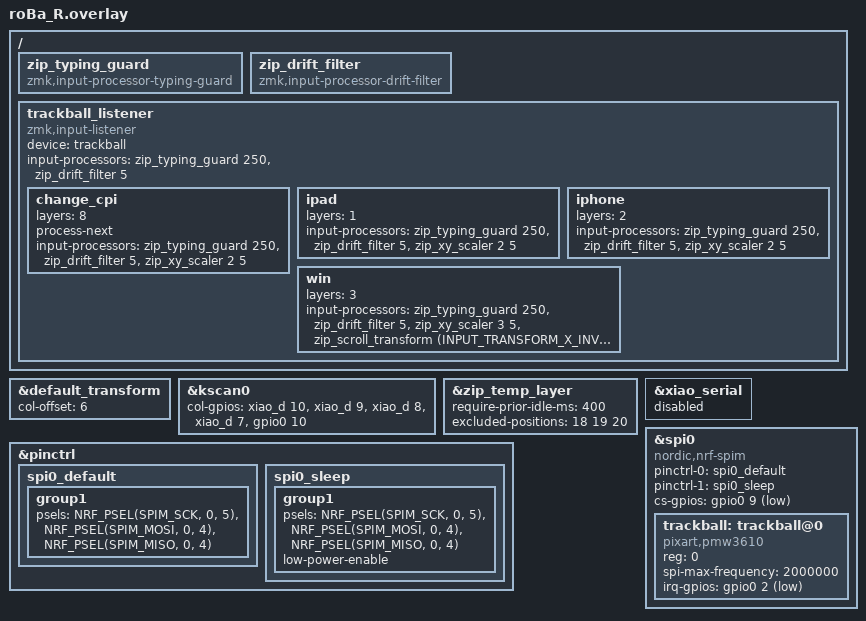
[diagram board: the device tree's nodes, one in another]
#include "roBa.dtsi"
#include <input/processors.dtsi>
#include <dt-bindings/zmk/input_transform.h>

&default_transform {
    col-offset = <6>;
};

&kscan0 {
        col-gpios
            = <&xiao_d 10 GPIO_ACTIVE_HIGH>
            , <&xiao_d 9 GPIO_ACTIVE_HIGH>
            , <&xiao_d 8 GPIO_ACTIVE_HIGH>
            , <&xiao_d 7 GPIO_ACTIVE_HIGH>
            , <&gpio0 10 GPIO_ACTIVE_HIGH>
            ;
};

/ {
    // 【検証中・2026-08-18】AML(自動マウスレイヤー)を一時的に全チェーンから外している。
    // カーソルのドリフトが「AMLの誤起動→K が中クリック化・文字カーソル飛び」という
    // 下流の症状を引き起こしていたため、AMLを切って純粋なドリフトだけを観察する。
    // クリックはレイヤー非依存のコンボ(J+K=左 / K+L=右 / J+L=中)で代替できる。
    // 復元する場合: git のタグ backup-2026-08-18-before-aml-disable を参照。
    // 直前のキー打鍵から指定ms以内はトラックボールのX/Y移動量を0に潰す。
    // ベアリング増設+ガスケットマウントケース化でボールが極めて高感度になり、
    // 連続タイピング中の打鍵振動がそのままカーソル移動として報告される問題への対策。
    // STOPで破棄する方式はv0.3-branchのinput_listenerがprocess-nextなし子ノード
    // (ipad/iphone/win)内でSTOPを握り潰す仕様のため使えず、value=0方式を採用
    // （全チェーンで位置に依らず確実に効く）。スクロール(WHEEL/HWHEEL)は対象外。
    zip_typing_guard: zip_typing_guard {
        compatible = "zmk,input-processor-typing-guard";
        #input-processor-cells = <1>;
    };

    // ゆっくりした一方向のドリフト(BLE接続時のカーソル暴走)を遮断する。
    // 実測: 100msあたりのイベント数が 通常操作=約9.4個 / ドリフト=約2.1個 と4倍以上
    // 差がつくため、窓内のイベント数が閾値未満なら「ドリフト」とみなして0にする。
    // 副次効果でマウスレイヤーの誤起動(K=中クリック化・文字カーソル飛び)も止まる。
    zip_drift_filter: zip_drift_filter {
        compatible = "zmk,input-processor-drift-filter";
        #input-processor-cells = <1>;
    };

    trackball_listener {
        status = "okay";
        compatible = "zmk,input-listener";
        device = <&trackball>;

        // 自動マウス層をOS別に出し分ける（ドライバのautomouse-layerは無効化済み）。
        // ベース（Mac等、Win以外）: 移動で層4(MOUSE)を一時有効化。
        input-processors = <&zip_typing_guard 250>, <&zip_drift_filter 5>;

        // 精密モード(層8 CHANGE_CPI)がONの間だけカーソルを×2/5(0.4倍)に。
        // process-next で後続のOS別子ノード＋baseへ連鎖するので、temp_layer遷移や
        // Winのスクロール反転はそのまま維持される（zip_xy_scalerはX/Yのみ）。
        // 定義順・名前順ともに先頭なので最初に評価される。
        change_cpi {
            layers = <8>;
            process-next;
            input-processors = <&zip_typing_guard 250>, <&zip_drift_filter 5>, <&zip_xy_scaler 2 5>;
        };

        // iPad（デフォルト層1がアクティブ）の上書き:
        //  移動で層5(MOUSE_ipad)を一時有効化。マウス層からの戻り先もiPad(1)。
        //  スクロール反転はしない（iPadはMac同様の向き）。
        ipad {
            layers = <1>;
            // iPadもソフト倍率化: base1000×2/5=実効400（精密モード(層8)がsnipe判定を
            // 壊す問題を回避するため snipe廃止）。精密ON時は change_cpi(×2/5)が
            // さらに掛かり実効160になる。
            input-processors = <&zip_typing_guard 250>, <&zip_drift_filter 5>, <&zip_xy_scaler 2 5>;
        };

        iphone {
            layers = <2>;
            // iPhoneは通常CPI(1000)を0.4倍=実効400に（緩やかなので滑らか）
            input-processors =
                <&zip_typing_guard 250>, <&zip_drift_filter 5>,
                <&zip_xy_scaler 2 5>;
        };

        // Windows（デフォルト層3がアクティブ）の上書き:
        //  - 移動で層7(MOUSE_win)を一時有効化（3より上なので隠れず、
        //    マウス層からの戻り先もWindows(3)になる）
        //  - カーソルを0.6倍=実効600に（zip_xy_scaler 3 5）。物理CPIはグローバル
        //    (Mac共通1000)なので下げられず、ソフト倍率でWindowsだけ分離する。
        //    Windows側「ポインターの速度」は初期値10(等倍)に戻す前提。
        //  - スクロールを縦横とも反転（zip_scroll_transformはWHEEL/HWHEELのみ、
        //    カーソル移動は不変）
        win {
            layers = <3>;
            input-processors =
                <&zip_typing_guard 250>, <&zip_drift_filter 5>,
                <&zip_xy_scaler 3 5>,
                <&zip_scroll_transform (INPUT_TRANSFORM_X_INVERT | INPUT_TRANSFORM_Y_INVERT)>;
        };
    };
};

// タイピング中のAML誤爆防止: 直前のキー入力から200ms間はマウス層を起動しない。
// require-prior-idle-ms は「起動抑制」のみ。キー押下による“即解除”とは別物なので、
// マウス層上の &kp（⌘W等）が壊れる問題は起きない（速すぎ/遅すぎれば数値調整）。
&zip_temp_layer {
    // 2026-07: ベアリング増設(3軸化)+ガスケットマウントケース化でボールが極めて
    // 高感度になり、連続タイピング中の打鍵振動がAMLを誤起動させカーソルが飛ぶ
    // 症状が出たため 200→400 に延長。CONFIG_PMW3610_MOVEMENT_THRESHOLD は
    // automouse-layer無効時(roBaは-1)は死んでいるコードパスのため無効(要確認済み)。
    require-prior-idle-ms = <400>;

    // 2026-08: 打鍵でマウス層を即解除する。require-prior-idle-ms は「起動抑制」
    // だけなので、タイピングの合間(400ms超)にドリフトでAMLが起動すると、その後
    // 10秒間ずっと居座り、J/K/L位置がクリックのままになって文字カーソルが飛ぶ、
    // Kが打てない、という症状が出ていた。
    // 除外するのはマウスボタンの位置(J=18/K=19/L=20)のみ。ここを押したときだけ
    // 層を維持してクリックが機能し、それ以外のキーを打つと即座に層が抜ける。
    // 旧コメントは「マウス層の&kp(⌘W等)が壊れる」ことを懸念して未設定としていたが、
    // 現在のMOUSE層を1キーずつ照合した結果、デフォルト層と挙動が異なるのは
    // 18/19/20 だけで、他は &to_layer_0 X と &kp X で結果が同じだった。
    excluded-positions = <18 19 20>;
};

&pinctrl {
    spi0_default: spi0_default {
        group1 {
            psels = <NRF_PSEL(SPIM_SCK, 0, 5)>,
                <NRF_PSEL(SPIM_MOSI, 0, 4)>,
                <NRF_PSEL(SPIM_MISO, 0, 4)>;
        };
    };

    spi0_sleep: spi0_sleep {
        group1 {
            psels = <NRF_PSEL(SPIM_SCK, 0, 5)>,
                <NRF_PSEL(SPIM_MOSI, 0, 4)>,
                <NRF_PSEL(SPIM_MISO, 0, 4)>;
            low-power-enable;
        };
    };
};

&xiao_serial { status = "disabled"; };

&spi0 {
    status = "okay";
    compatible = "nordic,nrf-spim";
    pinctrl-0 = <&spi0_default>;
    pinctrl-1 = <&spi0_sleep>;
    pinctrl-names = "default", "sleep";
    cs-gpios = <&gpio0 9 GPIO_ACTIVE_LOW>;

    trackball: trackball@0 {
        status = "okay";
        compatible = "pixart,pmw3610";
        reg = <0>;
        spi-max-frequency = <2000000>;
        irq-gpios = <&gpio0 2 (GPIO_ACTIVE_LOW | GPIO_PULL_UP)>;
    };
};
